# earlgrey register map
Vendor: lowRISC; File version: 0.1
CPU: ibex rev01, little endian, no MPU, no FPU, VTOR, 2 interrupt priority bits, 2 interrupts
Registers are 32-bit, read-write, no defined reset value unless marked. A register's access mark holds for its fields unless they carry their own. Offsets are from the block's base; [hi:lo] are bit positions; {n}, {i} and the like mark numbered series; 'fields as' and 'values as' point back to an identical list.

## ALERT_HANDLER
Base 0x40150000
0x40 PING_TIMER_REGWEN — Register write enable for !!PING_TIMEOUT_CYC_SHADOWED and !!PING_TIMER_EN_SHADOWED.
  [0] Value — When true, the !!PING_TIMEOUT_CYC_SHADOWED and !!PING_TIMER_EN_SHADOWED registers can be modified.When false, they become read-only. Defaults true, write one to clear.This should be cleared once the alert handler has been configured and the pingtimer mechanism has been kicked off.
0x44 PING_TIMEOUT_CYC_SHADOWED — Ping timeout cycle count.
  [15:0] Value — Timeout value in cycles.If an alert receiver or an escalation sender does not respond to a ping within this timeout window, a pingfail alert will be raised.It is recommended to set this value to the equivalent of 256 cycles of the slowest alert sender clock domain in the system (or greater).
0x48 PING_TIMER_EN_SHADOWED — Ping timer enable.
  [0] Value — Setting this to 1 enables the ping timer mechanism.This bit cannot be cleared to 0 once it has been set to 1.Note that the alert pinging mechanism will only ping alerts that have been enabled and locked.
{0x4C+4i} ALERT_REGWEN_{i} (i=0..64) — Register write enable for alert enable bits.
  [0] EN — Alert configuration write enable bit.If this is cleared to 0, the corresponding !!ALERT_EN_SHADOWEDand !!ALERT_CLASS_SHADOWED bits are not writable anymore.Note that the alert pinging mechanism will only ping alerts that have been enabled and locked.
{0x150+4i} ALERT_EN_SHADOWED_{i} (i=0..64) — Enable register for alerts.
  [0] EN_A — Alert enable bit.Note that the alert pinging mechanism will only ping alerts that have been enabled and locked.
{0x254+4i} ALERT_CLASS_SHADOWED_{i} (i=0..64) — Class assignment of alerts.
  [1:0] CLASS_A — Classification
{0x358+4i} ALERT_CAUSE_{i} (i=0..64) — Alert Cause Register
  [0] A — Cause bit
{0x45C+4i} LOC_ALERT_REGWEN_{i} (i=0..6) — Register write enable for alert enable bits.
  [0] EN — Alert configuration write enable bit.If this is cleared to 0, the corresponding !!LOC_ALERT_EN_SHADOWEDand !!LOC_ALERT_CLASS_SHADOWED bits are not writable anymore.Note that the alert pinging mechanism will only ping alerts that have been enabled and locked.
{0x478+4i} LOC_ALERT_EN_SHADOWED_{i} (i=0..6) — Enable register for the local alerts"alert pingfail" (0), "escalation pingfail" (1),"alert integfail" (2), "escalation integfail" (3),"bus integrity failure" (4), "shadow reg update error" (5)and "shadow reg storage error" (6).
  [0] EN_LA — Alert enable bit.Note that the alert pinging mechanism will only ping alerts that have been enabled and locked.
{0x494+4i} LOC_ALERT_CLASS_SHADOWED_{i} (i=0..6) — Class assignment of the local alerts"alert pingfail" (0), "escalation pingfail" (1),"alert integfail" (2), "escalation integfail" (3),"bus integrity failure" (4), "shadow reg update error" (5)and "shadow reg storage error" (6).
  [1:0] CLASS_LA — Classification
{0x4B0+4i} LOC_ALERT_CAUSE_{i} (i=0..6) — Alert Cause Register for the local alerts"alert pingfail" (0), "escalation pingfail" (1),"alert integfail" (2), "escalation integfail" (3),"bus integrity failure" (4), "shadow reg update error" (5)and "shadow reg storage error" (6).
  [0] LA — Cause bit
0x4CC CLASSA_REGWEN — Lock bit for Class A configuration.
  [0] Value — Class configuration enable bit.If this is cleared to 0, the corresponding class configurationregisters cannot be written anymore.
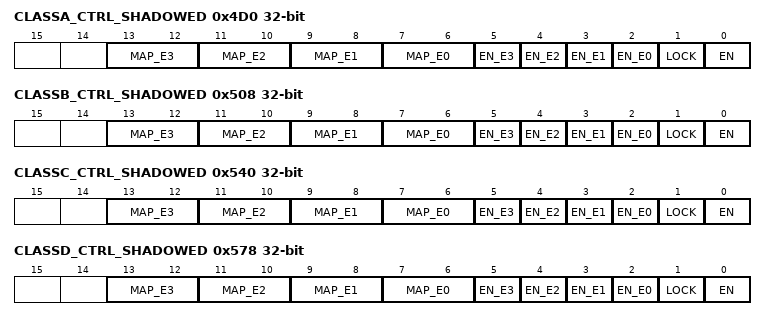
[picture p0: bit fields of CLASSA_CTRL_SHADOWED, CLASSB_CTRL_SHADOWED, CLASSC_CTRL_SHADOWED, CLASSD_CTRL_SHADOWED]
0x4D0 CLASSA_CTRL_SHADOWED — Escalation control register for alert Class A. Can not be modified if !!CLASSA_REGWEN is false.
  [2n+7:2n+6] MAP_E{n} (n=0..3) — Determines in which escalation phase escalation signal {n} shall be asserted.
  [n+2] EN_E{n} (n=0..3) — Enable escalation signal {n} for Class A
  [1] LOCK — Enable automatic locking of escalation counter for class A.If true, there is no way to stop the escalation protocol for class Aonce it has been triggered.
  [0] EN — Enable escalation mechanisms (accumulation andinterrupt timeout) for Class A. Note that interrupts can fireregardless of whether the escalation mechanisms are enabled forthis class or not.
0x4D4 CLASSA_CLR_REGWEN — Clear enable for escalation protocol of Class A alerts.
  [0] Value — Register defaults to true, can only be cleared. This register is setto false by the hardware if the escalation protocol has been triggered and the bit!!CLASSA_CTRL_SHADOWED.LOCK is true.
0x4D8 CLASSA_CLR_SHADOWED — Clear for escalation protocol of Class A.
  [0] Value — Writing 1 to this register clears the accumulator and aborts escalation(if it has been triggered). This clear is disabled if !!CLASSA_CLR_REGWEN is false.
0x4DC CLASSA_ACCUM_CNT ro — Current accumulation value for alert Class A. Software can clear this registerwith a write to !!CLASSA_CLR_SHADOWED register unless !!CLASSA_CLR_REGWEN is false.
  [15:0] Value
0x4E0 CLASSA_ACCUM_THRESH_SHADOWED — Accumulation threshold value for alert Class A.
  [15:0] Value — Once the accumulation value register is equal to the threshold escalation willbe triggered on the next alert occurrence within this class A begins. Note that thisregister can not be modified if !!CLASSA_REGWEN is false.
0x4E4 CLASSA_TIMEOUT_CYC_SHADOWED — Interrupt timeout in cycles.
  [31:0] Value — If the interrupt corresponding to this class is nothandled within the specified amount of cycles, escalation will be triggered.Set to a positive value to enable the interrupt timeout for Class A. The timeout is set to zeroby default, which disables this feature. Note that this register can not be modified if!!CLASSA_REGWEN is false.
0x4E8 CLASSA_CRASHDUMP_TRIGGER_SHADOWED — Crashdump trigger configuration for Class A.
  [1:0] Value — Determine in which escalation phase to capture the crashdump containing all alert cause CSRs and escalationtimer states. It is recommended to capture the crashdump upon entering the first escalation phasethat activates a countermeasure with many side-effects (e.g. life cycle state scrapping) in orderto prevent spurious alert events from masking the original alert causes.Note that this register can not be modified if !!CLASSA_REGWEN is false.
{0x4EC+4i} CLASSA_PHASE{i}_CYC_SHADOWED (i=0..3) — Duration of escalation phase {i} for Class A.
  [31:0] Value — Escalation phase duration in cycles. Note that this register can not bemodified if !!CLASSA_REGWEN is false.
0x4FC CLASSA_ESC_CNT ro — Escalation counter in cycles for Class A.
  [31:0] Value — Returns the current timeout or escalation count (depending on !!CLASSA_STATE).This register can not be directly cleared. However, SW can indirectly clear as follows.If the class is in the Timeout state, the timeout can be aborted by clearing thecorresponding interrupt bit.If this class is in any of the escalation phases (e.g. Phase0), escalation protocol can beaborted by writing to !!CLASSA_CLR_SHADOWED. Note however that has no effect if !!CLASSA_REGWENis set to false (either by SW or by HW via the !!CLASSA_CTRL_SHADOWED.LOCK feature).
0x500 CLASSA_STATE ro — Current escalation state of Class A. See also !!CLASSA_ESC_CNT.
  [2:0] Value
0x504 CLASSB_REGWEN — Lock bit for Class B configuration.
  fields as CLASSA_REGWEN
0x508 CLASSB_CTRL_SHADOWED — Escalation control register for alert Class B. Can not be modified if !!CLASSB_REGWEN is false.
  [2n+7:2n+6] MAP_E{n} (n=0..3) — Determines in which escalation phase escalation signal {n} shall be asserted.
  [n+2] EN_E{n} (n=0..3) — Enable escalation signal {n} for Class B
  [1] LOCK — Enable automatic locking of escalation counter for class B.If true, there is no way to stop the escalation protocol for class Bonce it has been triggered.
  [0] EN — Enable escalation mechanisms (accumulation andinterrupt timeout) for Class B. Note that interrupts can fireregardless of whether the escalation mechanisms are enabled forthis class or not.
0x50C CLASSB_CLR_REGWEN — Clear enable for escalation protocol of Class B alerts.
  [0] Value — Register defaults to true, can only be cleared. This register is setto false by the hardware if the escalation protocol has been triggered and the bit!!CLASSB_CTRL_SHADOWED.LOCK is true.
0x510 CLASSB_CLR_SHADOWED — Clear for escalation protocol of Class B.
  [0] Value — Writing 1 to this register clears the accumulator and aborts escalation(if it has been triggered). This clear is disabled if !!CLASSB_CLR_REGWEN is false.
0x514 CLASSB_ACCUM_CNT ro — Current accumulation value for alert Class B. Software can clear this registerwith a write to !!CLASSB_CLR_SHADOWED register unless !!CLASSB_CLR_REGWEN is false.
  [15:0] Value
0x518 CLASSB_ACCUM_THRESH_SHADOWED — Accumulation threshold value for alert Class B.
  [15:0] Value — Once the accumulation value register is equal to the threshold escalation willbe triggered on the next alert occurrence within this class B begins. Note that thisregister can not be modified if !!CLASSB_REGWEN is false.
0x51C CLASSB_TIMEOUT_CYC_SHADOWED — Interrupt timeout in cycles.
  [31:0] Value — If the interrupt corresponding to this class is nothandled within the specified amount of cycles, escalation will be triggered.Set to a positive value to enable the interrupt timeout for Class B. The timeout is set to zeroby default, which disables this feature. Note that this register can not be modified if!!CLASSB_REGWEN is false.
0x520 CLASSB_CRASHDUMP_TRIGGER_SHADOWED — Crashdump trigger configuration for Class B.
  [1:0] Value — Determine in which escalation phase to capture the crashdump containing all alert cause CSRs and escalationtimer states. It is recommended to capture the crashdump upon entering the first escalation phasethat activates a countermeasure with many side-effects (e.g. life cycle state scrapping) in orderto prevent spurious alert events from masking the original alert causes.Note that this register can not be modified if !!CLASSB_REGWEN is false.
{0x524+4i} CLASSB_PHASE{i}_CYC_SHADOWED (i=0..3) — Duration of escalation phase {i} for Class B.
  [31:0] Value — Escalation phase duration in cycles. Note that this register can not bemodified if !!CLASSB_REGWEN is false.
0x534 CLASSB_ESC_CNT ro — Escalation counter in cycles for Class B.
  [31:0] Value — Returns the current timeout or escalation count (depending on !!CLASSB_STATE).This register can not be directly cleared. However, SW can indirectly clear as follows.If the class is in the Timeout state, the timeout can be aborted by clearing thecorresponding interrupt bit.If this class is in any of the escalation phases (e.g. Phase0), escalation protocol can beaborted by writing to !!CLASSB_CLR_SHADOWED. Note however that has no effect if !!CLASSB_REGWENis set to false (either by SW or by HW via the !!CLASSB_CTRL_SHADOWED.LOCK feature).
0x538 CLASSB_STATE ro — Current escalation state of Class B. See also !!CLASSB_ESC_CNT.
  [2:0] Value
0x53C CLASSC_REGWEN — Lock bit for Class C configuration.
  fields as CLASSA_REGWEN
0x540 CLASSC_CTRL_SHADOWED — Escalation control register for alert Class C. Can not be modified if !!CLASSC_REGWEN is false.
  [2n+7:2n+6] MAP_E{n} (n=0..3) — Determines in which escalation phase escalation signal {n} shall be asserted.
  [n+2] EN_E{n} (n=0..3) — Enable escalation signal {n} for Class C
  [1] LOCK — Enable automatic locking of escalation counter for class C.If true, there is no way to stop the escalation protocol for class Conce it has been triggered.
  [0] EN — Enable escalation mechanisms (accumulation andinterrupt timeout) for Class C. Note that interrupts can fireregardless of whether the escalation mechanisms are enabled forthis class or not.
0x544 CLASSC_CLR_REGWEN — Clear enable for escalation protocol of Class C alerts.
  [0] Value — Register defaults to true, can only be cleared. This register is setto false by the hardware if the escalation protocol has been triggered and the bit!!CLASSC_CTRL_SHADOWED.LOCK is true.
0x548 CLASSC_CLR_SHADOWED — Clear for escalation protocol of Class C.
  [0] Value — Writing 1 to this register clears the accumulator and aborts escalation(if it has been triggered). This clear is disabled if !!CLASSC_CLR_REGWEN is false.
0x54C CLASSC_ACCUM_CNT ro — Current accumulation value for alert Class C. Software can clear this registerwith a write to !!CLASSC_CLR_SHADOWED register unless !!CLASSC_CLR_REGWEN is false.
  [15:0] Value
0x550 CLASSC_ACCUM_THRESH_SHADOWED — Accumulation threshold value for alert Class C.
  [15:0] Value — Once the accumulation value register is equal to the threshold escalation willbe triggered on the next alert occurrence within this class C begins. Note that thisregister can not be modified if !!CLASSC_REGWEN is false.
0x554 CLASSC_TIMEOUT_CYC_SHADOWED — Interrupt timeout in cycles.
  [31:0] Value — If the interrupt corresponding to this class is nothandled within the specified amount of cycles, escalation will be triggered.Set to a positive value to enable the interrupt timeout for Class C. The timeout is set to zeroby default, which disables this feature. Note that this register can not be modified if!!CLASSC_REGWEN is false.
0x558 CLASSC_CRASHDUMP_TRIGGER_SHADOWED — Crashdump trigger configuration for Class C.
  [1:0] Value — Determine in which escalation phase to capture the crashdump containing all alert cause CSRs and escalationtimer states. It is recommended to capture the crashdump upon entering the first escalation phasethat activates a countermeasure with many side-effects (e.g. life cycle state scrapping) in orderto prevent spurious alert events from masking the original alert causes.Note that this register can not be modified if !!CLASSC_REGWEN is false.
{0x55C+4i} CLASSC_PHASE{i}_CYC_SHADOWED (i=0..3) — Duration of escalation phase {i} for Class C.
  [31:0] Value — Escalation phase duration in cycles. Note that this register can not bemodified if !!CLASSC_REGWEN is false.
0x56C CLASSC_ESC_CNT ro — Escalation counter in cycles for Class C.
  [31:0] Value — Returns the current timeout or escalation count (depending on !!CLASSC_STATE).This register can not be directly cleared. However, SW can indirectly clear as follows.If the class is in the Timeout state, the timeout can be aborted by clearing thecorresponding interrupt bit.If this class is in any of the escalation phases (e.g. Phase0), escalation protocol can beaborted by writing to !!CLASSC_CLR_SHADOWED. Note however that has no effect if !!CLASSC_REGWENis set to false (either by SW or by HW via the !!CLASSC_CTRL_SHADOWED.LOCK feature).
0x570 CLASSC_STATE ro — Current escalation state of Class C. See also !!CLASSC_ESC_CNT.
  [2:0] Value
0x574 CLASSD_REGWEN — Lock bit for Class D configuration.
  fields as CLASSA_REGWEN
0x578 CLASSD_CTRL_SHADOWED — Escalation control register for alert Class D. Can not be modified if !!CLASSD_REGWEN is false.
  [2n+7:2n+6] MAP_E{n} (n=0..3) — Determines in which escalation phase escalation signal {n} shall be asserted.
  [n+2] EN_E{n} (n=0..3) — Enable escalation signal {n} for Class D
  [1] LOCK — Enable automatic locking of escalation counter for class D.If true, there is no way to stop the escalation protocol for class Donce it has been triggered.
  [0] EN — Enable escalation mechanisms (accumulation andinterrupt timeout) for Class D. Note that interrupts can fireregardless of whether the escalation mechanisms are enabled forthis class or not.
0x57C CLASSD_CLR_REGWEN — Clear enable for escalation protocol of Class D alerts.
  [0] Value — Register defaults to true, can only be cleared. This register is setto false by the hardware if the escalation protocol has been triggered and the bit!!CLASSD_CTRL_SHADOWED.LOCK is true.
0x580 CLASSD_CLR_SHADOWED — Clear for escalation protocol of Class D.
  [0] Value — Writing 1 to this register clears the accumulator and aborts escalation(if it has been triggered). This clear is disabled if !!CLASSD_CLR_REGWEN is false.
0x584 CLASSD_ACCUM_CNT ro — Current accumulation value for alert Class D. Software can clear this registerwith a write to !!CLASSD_CLR_SHADOWED register unless !!CLASSD_CLR_REGWEN is false.
  [15:0] Value
0x588 CLASSD_ACCUM_THRESH_SHADOWED — Accumulation threshold value for alert Class D.
  [15:0] Value — Once the accumulation value register is equal to the threshold escalation willbe triggered on the next alert occurrence within this class D begins. Note that thisregister can not be modified if !!CLASSD_REGWEN is false.
0x58C CLASSD_TIMEOUT_CYC_SHADOWED — Interrupt timeout in cycles.
  [31:0] Value — If the interrupt corresponding to this class is nothandled within the specified amount of cycles, escalation will be triggered.Set to a positive value to enable the interrupt timeout for Class D. The timeout is set to zeroby default, which disables this feature. Note that this register can not be modified if!!CLASSD_REGWEN is false.
0x590 CLASSD_CRASHDUMP_TRIGGER_SHADOWED — Crashdump trigger configuration for Class D.
  [1:0] Value — Determine in which escalation phase to capture the crashdump containing all alert cause CSRs and escalationtimer states. It is recommended to capture the crashdump upon entering the first escalation phasethat activates a countermeasure with many side-effects (e.g. life cycle state scrapping) in orderto prevent spurious alert events from masking the original alert causes.Note that this register can not be modified if !!CLASSD_REGWEN is false.
{0x594+4i} CLASSD_PHASE{i}_CYC_SHADOWED (i=0..3) — Duration of escalation phase {i} for Class D.
  [31:0] Value — Escalation phase duration in cycles. Note that this register can not bemodified if !!CLASSD_REGWEN is false.
0x5A4 CLASSD_ESC_CNT ro — Escalation counter in cycles for Class D.
  [31:0] Value — Returns the current timeout or escalation count (depending on !!CLASSD_STATE).This register can not be directly cleared. However, SW can indirectly clear as follows.If the class is in the Timeout state, the timeout can be aborted by clearing thecorresponding interrupt bit.If this class is in any of the escalation phases (e.g. Phase0), escalation protocol can beaborted by writing to !!CLASSD_CLR_SHADOWED. Note however that has no effect if !!CLASSD_REGWENis set to false (either by SW or by HW via the !!CLASSD_CTRL_SHADOWED.LOCK feature).
0x5A8 CLASSD_STATE ro — Current escalation state of Class D. See also !!CLASSD_ESC_CNT.
  [2:0] Value
